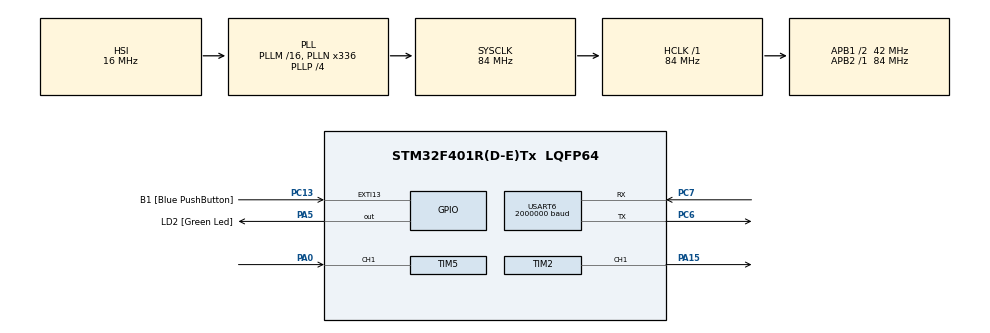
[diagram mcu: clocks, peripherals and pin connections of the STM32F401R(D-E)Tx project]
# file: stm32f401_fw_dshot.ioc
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Dma.Request0=TIM2_CH1
Dma.Request1=TIM5_CH1
Dma.TIM2_CH1.0.Direction=DMA_MEMORY_TO_PERIPH
Dma.TIM2_CH1.0.FIFOMode=DMA_FIFOMODE_ENABLE
Dma.TIM2_CH1.0.FIFOThreshold=DMA_FIFO_THRESHOLD_FULL
Dma.TIM2_CH1.0.Instance=DMA1_Stream5
Dma.TIM2_CH1.0.MemBurst=DMA_MBURST_SINGLE
Dma.TIM2_CH1.0.MemDataAlignment=DMA_MDATAALIGN_WORD
Dma.TIM2_CH1.0.MemInc=DMA_MINC_ENABLE
Dma.TIM2_CH1.0.Mode=DMA_NORMAL
Dma.TIM2_CH1.0.PeriphBurst=DMA_PBURST_SINGLE
Dma.TIM2_CH1.0.PeriphDataAlignment=DMA_PDATAALIGN_WORD
Dma.TIM2_CH1.0.PeriphInc=DMA_PINC_DISABLE
Dma.TIM2_CH1.0.Priority=DMA_PRIORITY_HIGH
Dma.TIM5_CH1.1.Direction=DMA_PERIPH_TO_MEMORY
Dma.TIM5_CH1.1.FIFOMode=DMA_FIFOMODE_ENABLE
Dma.TIM5_CH1.1.FIFOThreshold=DMA_FIFO_THRESHOLD_FULL
Dma.TIM5_CH1.1.Instance=DMA1_Stream2
Dma.TIM5_CH1.1.MemBurst=DMA_MBURST_SINGLE
Dma.TIM5_CH1.1.MemDataAlignment=DMA_MDATAALIGN_WORD
Dma.TIM5_CH1.1.MemInc=DMA_MINC_ENABLE
Dma.TIM5_CH1.1.Mode=DMA_CIRCULAR
Dma.TIM5_CH1.1.PeriphBurst=DMA_PBURST_SINGLE
Dma.TIM5_CH1.1.PeriphDataAlignment=DMA_PDATAALIGN_WORD
Dma.TIM5_CH1.1.PeriphInc=DMA_PINC_DISABLE
Dma.TIM5_CH1.1.Priority=DMA_PRIORITY_LOW
Mcu.Family=STM32F4
Mcu.Name=STM32F401R(D-E)Tx
Mcu.Package=LQFP64
NVIC.DMA1_Stream2_IRQn=true\:0\:0\:false\:false\:true\:false\:true\:true
NVIC.DMA1_Stream5_IRQn=true\:0\:0\:false\:false\:true\:false\:true\:true
NVIC.EXTI15_10_IRQn=true\:0\:0\:false\:false\:true\:true\:true\:true
NVIC.PriorityGroup=NVIC_PRIORITYGROUP_0
NVIC.TIM5_IRQn=true\:0\:0\:false\:false\:true\:true\:true\:true
PA0-WKUP.GPIO_Speed=GPIO_SPEED_FREQ_VERY_HIGH
PA0-WKUP.Signal=S_TIM5_CH1
PA13.GPIO_Label=TMS
PA13.Mode=Serial_Wire
PA13.Signal=SYS_JTMS-SWDIO
PA14.GPIO_Label=TCK
PA14.Mode=Serial_Wire
PA14.Signal=SYS_JTCK-SWCLK
PA15.GPIO_Speed=GPIO_SPEED_FREQ_VERY_HIGH
PA15.Signal=S_TIM2_CH1_ETR
PA2.GPIO_Label=USART_TX
PA2.GPIO_Mode=GPIO_MODE_AF_PP
PA2.GPIO_PuPd=GPIO_NOPULL
PA2.GPIO_Speed=GPIO_SPEED_FREQ_LOW
PA2.Signal=USART2_TX
PA3.GPIO_Label=USART_RX
PA3.GPIO_Mode=GPIO_MODE_AF_PP
PA3.GPIO_PuPd=GPIO_NOPULL
PA3.GPIO_Speed=GPIO_SPEED_FREQ_LOW
PA3.Signal=USART2_RX
PA5.GPIO_Label=LD2 [Green Led]
PA5.GPIO_Mode=GPIO_MODE_OUTPUT_PP
PA5.GPIO_PuPd=GPIO_NOPULL
PA5.GPIO_Speed=GPIO_SPEED_FREQ_LOW
PA5.Signal=GPIO_Output
PB3.GPIO_Label=SWO
PB3.Signal=SYS_JTDO-SWO
PC13-ANTI_TAMP.GPIO_Label=B1 [Blue PushButton]
PC13-ANTI_TAMP.GPIO_ModeDefaultEXTI=GPIO_MODE_IT_FALLING
PC13-ANTI_TAMP.GPIO_PuPd=GPIO_NOPULL
PC13-ANTI_TAMP.Signal=GPXTI13
PC14-OSC32_IN.Mode=LSE-External-Oscillator
PC14-OSC32_IN.Signal=RCC_OSC32_IN
PC15-OSC32_OUT.Mode=LSE-External-Oscillator
PC15-OSC32_OUT.Signal=RCC_OSC32_OUT
PC6.Mode=Asynchronous
PC6.Signal=USART6_TX
PC7.Mode=Asynchronous
PC7.Signal=USART6_RX
PH0\ -\ OSC_IN.Mode=HSE-External-Clock-Source
PH0\ -\ OSC_IN.Signal=RCC_OSC_IN
PH1\ -\ OSC_OUT.Mode=HSE-External-Clock-Source
PH1\ -\ OSC_OUT.Signal=RCC_OSC_OUT
ProjectManager.HeapSize=0x200
ProjectManager.StackSize=0x400
ProjectManager.TargetToolchain=STM32CubeIDE
RCC.48MHZClocksFreq_Value=48000000
RCC.AHBFreq_Value=84000000
RCC.APB1CLKDivider=RCC_HCLK_DIV2
RCC.APB1Freq_Value=42000000
RCC.APB1TimFreq_Value=84000000
RCC.APB2Freq_Value=84000000
RCC.APB2TimFreq_Value=84000000
RCC.CortexFreq_Value=84000000
RCC.HCLKFreq_Value=84000000
RCC.HSE_VALUE=8000000
RCC.HSI_VALUE=16000000
RCC.PLLN=336
RCC.PLLP=RCC_PLLP_DIV4
RCC.PLLQ=7
RCC.SYSCLKFreq_VALUE=84000000
RCC.SYSCLKSource=RCC_SYSCLKSOURCE_PLLCLK
RCC.VCOOutputFreq_Value=336000000
SH.S_TIM2_CH1_ETR.0=TIM2_CH1,PWM Generation1 CH1
SH.S_TIM5_CH1.0=TIM5_CH1,PWM_Input_1
TIM2.Channel-PWM\ Generation1\ CH1=TIM_CHANNEL_1
TIM2.OCPolarity_1=TIM_OCPOLARITY_HIGH
TIM2.Period=0
TIM5.ICPolarity_1=TIM_INPUTCHANNELPOLARITY_FALLING
USART6.BaudRate=2000000
USART6.VirtualMode=VM_ASYNC
VP_TIM5_VS_ClockSourceINT.Mode=Internal
board=NUCLEO-F401RE

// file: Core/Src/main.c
/* USER CODE BEGIN Header */
/**
  ******************************************************************************
  * @file           : main.c
  * @brief          : Main program body
  ******************************************************************************
  * @attention
  *
  * Copyright (c) 2024 STMicroelectronics.
  * All rights reserved.
  *
  * This software is licensed under terms that can be found in the LICENSE file
  * in the root directory of this software component.
  * If no LICENSE file comes with this software, it is provided AS-IS.
  *
  ******************************************************************************
  */
/* USER CODE END Header */
#include "main.h"
#include "dma.h"
#include "tim.h"
#include "usart.h"
#include "gpio.h"

/* USER CODE BEGIN Includes */
#include "dshot.h"
/* USER CODE END Includes */

/* USER CODE BEGIN PV */
uint16_t my_motor_value = 0;

/* USER CODE END PV */

void SystemClock_Config(void);

/* USER CODE BEGIN 0 */
void HAL_GPIO_EXTI_Callback(uint16_t GPIO_Pin)
{
    if (GPIO_Pin == B1_Pin)
    {
		HAL_GPIO_TogglePin(GPIOA, GPIO_PIN_5);  // Toggle LED
		my_motor_value = (my_motor_value + 50) % 2000;  // Loop through thrust values
		uart_print("Button pressed\n");  // Send debug feedback
    }
}

/* USER CODE END 0 */

int main(void)
{

  /* MCU Configuration--------------------------------------------------------*/

  /* Reset of all peripherals, Initializes the Flash interface and the Systick. */
  HAL_Init();

  /* Configure the system clock */
  SystemClock_Config();

  /* Initialize all configured peripherals */
  MX_GPIO_Init();
  MX_DMA_Init();
  MX_TIM2_Init();
  MX_TIM5_Init();
  MX_USART6_UART_Init();
  /* USER CODE BEGIN 2 */

  dshot_init(DSHOT150);
  uart_print("DSHOT-300\n");

  if (reverse_dshot != 0)
  {
	  HAL_TIM_IC_Start_IT(&htim5, TIM_CHANNEL_1);  // Primary channel - falling edge
	  HAL_TIM_IC_Start(&htim5, TIM_CHANNEL_2);  // Secondary channel - rising edge
  }

  /* USER CODE END 2 */

  /* Infinite loop */
  /* USER CODE BEGIN WHILE */
  while (1)
  {
	dshot_write(my_motor_value);
	HAL_Delay(1);
    /* USER CODE END WHILE */

  }
}

void SystemClock_Config(void)
{
  RCC_OscInitTypeDef RCC_OscInitStruct = {0};
  RCC_ClkInitTypeDef RCC_ClkInitStruct = {0};

  /** Configure the main internal regulator output voltage
  */
  __HAL_RCC_PWR_CLK_ENABLE();
  __HAL_PWR_VOLTAGESCALING_CONFIG(PWR_REGULATOR_VOLTAGE_SCALE2);

  /** Initializes the RCC Oscillators according to the specified parameters
  * in the RCC_OscInitTypeDef structure.
  */
  RCC_OscInitStruct.OscillatorType = RCC_OSCILLATORTYPE_HSI;
  RCC_OscInitStruct.HSIState = RCC_HSI_ON;
  RCC_OscInitStruct.HSICalibrationValue = RCC_HSICALIBRATION_DEFAULT;
  RCC_OscInitStruct.PLL.PLLState = RCC_PLL_ON;
  RCC_OscInitStruct.PLL.PLLSource = RCC_PLLSOURCE_HSI;
  RCC_OscInitStruct.PLL.PLLM = 16;
  RCC_OscInitStruct.PLL.PLLN = 336;
  RCC_OscInitStruct.PLL.PLLP = RCC_PLLP_DIV4;
  RCC_OscInitStruct.PLL.PLLQ = 7;
  if (HAL_RCC_OscConfig(&RCC_OscInitStruct) != HAL_OK)
  {
    Error_Handler();
  }

  /** Initializes the CPU, AHB and APB buses clocks
  */
  RCC_ClkInitStruct.ClockType = RCC_CLOCKTYPE_HCLK|RCC_CLOCKTYPE_SYSCLK
                              |RCC_CLOCKTYPE_PCLK1|RCC_CLOCKTYPE_PCLK2;
  RCC_ClkInitStruct.SYSCLKSource = RCC_SYSCLKSOURCE_PLLCLK;
  RCC_ClkInitStruct.AHBCLKDivider = RCC_SYSCLK_DIV1;
  RCC_ClkInitStruct.APB1CLKDivider = RCC_HCLK_DIV2;
  RCC_ClkInitStruct.APB2CLKDivider = RCC_HCLK_DIV1;

  if (HAL_RCC_ClockConfig(&RCC_ClkInitStruct, FLASH_LATENCY_2) != HAL_OK)
  {
    Error_Handler();
  }
}

void Error_Handler(void)
{
  __disable_irq();
  while (1)
  {
  }
}
